# CY8C5868AXI_LP035 register map
File version: 0.1
CY8C58LP
Registers are 8-bit, read-write, no defined reset value unless marked. A register's access mark holds for its fields unless they carry their own. Offsets are from the block's base; lines under a group give offsets from that group; [hi:lo] are bit positions; {n}, {i} and the like mark numbered series; 'fields as' and 'values as' point back to an identical list; <NAME> marks a mode.

## Memory map
0x00000000 USBMIDI_1 — USBFS
0x00000000 MIDI1_UART — UART
0x00000000 Noise_Clk_Div
0x00000000 Tri_Divider
0x00000000 Length_Counter
0x00000000 Length_Counter_1
0x00000000 Counter_1
0x00000000 VDAC8_Noise
0x40006406 LFSR
0x40006471 volume_generator — Count7 debug registers
0x40006477 Control_Reg_2
0x4000647D Control_Reg_1
0x40006564 Status_Reg_1
0x40006574 Control_Reg_4
0x40006575 Count7_2 — Count7 debug registers
0x40006576 Noise_Vol_Clk_Div — Count7 debug registers
0x40006577 Count7_1 — Count7 debug registers
0x40006578 Control_Reg_3

## MIDI1_UART — UART
Base 0x00000000
0x4000642B RX_MIDI1_UART_RX_ADDRESS1 — RX Address1 Register
0x4000643B RX_MIDI1_UART_RX_ADDRESS2 — RX Address2 Register
0x4000644B RX_MIDI1_UART_RX_DATA — RX Data Register
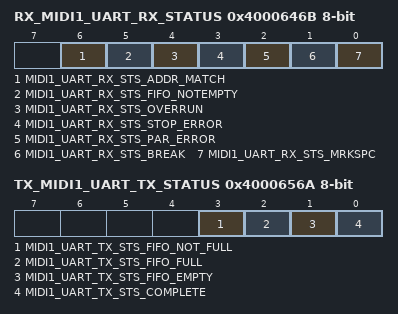
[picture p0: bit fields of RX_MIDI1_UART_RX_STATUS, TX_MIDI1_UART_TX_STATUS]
0x4000646B RX_MIDI1_UART_RX_STATUS — RX status register
  [6] MIDI1_UART_RX_STS_ADDR_MATCH ro, [5] MIDI1_UART_RX_STS_FIFO_NOTEMPTY ro, [4] MIDI1_UART_RX_STS_OVERRUN ro, [3] MIDI1_UART_RX_STS_STOP_ERROR ro, [2] MIDI1_UART_RX_STS_PAR_ERROR ro, [1] MIDI1_UART_RX_STS_BREAK ro, [0] MIDI1_UART_RX_STS_MRKSPC ro
0x4000654A TX_MIDI1_UART_TX_DATA — TX Data Register
0x4000656A TX_MIDI1_UART_TX_STATUS — TX status register
  [3] MIDI1_UART_TX_STS_FIFO_NOT_FULL ro, [2] MIDI1_UART_TX_STS_FIFO_FULL ro, [1] MIDI1_UART_TX_STS_FIFO_EMPTY ro, [0] MIDI1_UART_TX_STS_COMPLETE ro

## Count7_2 — Count7 debug registers
Base 0x40006575
Same registers: volume_generator 0x40006471, Noise_Vol_Clk_Div 0x40006576, Count7_1 0x40006577
0x00 COUNT 7-bit — Count value register
0x10 PERIOD 7-bit — Count7 period register

## Status_Reg_1
Base 0x40006564
0x00 Status_Reg_1_STATUS_REG
0x20 Status_Reg_1_MASK_REG
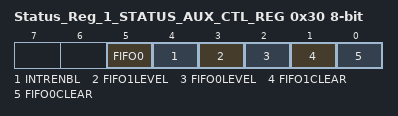
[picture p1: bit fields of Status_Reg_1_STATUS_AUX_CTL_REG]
0x30 Status_Reg_1_STATUS_AUX_CTL_REG
  [5] FIFO0 — FIFO0 clear
    1=ENABLED (Enable counter); 0=DISABLED (Disable counter)
  [4] INTRENBL — Enables or disables the Interrupt
    1=ENABLED (Interrupt enabled); 0=DISABLED (Interrupt disabled)
  [3] FIFO1LEVEL — FIFO level
    1=ENABLED (FIFO LVL: input mode: FIFO at least 1/2 empty; output mode: FIFO at least 1/2 full); 0=DISABLED (FIFO LVL: input mode: FIFO not full; output mode: FIFO not empty)
  [2] FIFO0LEVEL — FIFO level
    values as FIFO1LEVEL
  [1] FIFO1CLEAR — FIFO clear
    1=ENABLED (Clear FIFO state); 0=DISABLED (Normal FIFO operation)
  [0] FIFO0CLEAR — FIFO clear
    values as FIFO1CLEAR

## Control_Reg_3
Base 0x40006578
0x00 Control_Reg_3_CONTROL_REG

## Control_Reg_2
Base 0x40006477
Registers as Control_Reg_3 (with Control_Reg_3 read as Control_Reg_2).

## Control_Reg_4
Base 0x40006574
Registers as Control_Reg_3 (with Control_Reg_3 read as Control_Reg_4).

## Control_Reg_1
Base 0x4000647D
Registers as Control_Reg_3 (with Control_Reg_3 read as Control_Reg_1).

## Noise_Clk_Div
Base 0x00000000
0x400043A3 Noise_Clk_Div_GLOBAL_ENABLE — PM.ACT.CFG
  [3:0] en_timer — Enable timer/counters.
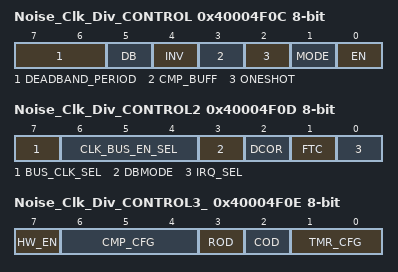
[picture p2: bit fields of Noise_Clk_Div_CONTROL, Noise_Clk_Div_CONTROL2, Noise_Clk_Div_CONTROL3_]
0x40004F0C Noise_Clk_Div_CONTROL — TMRx.CFG0
  [7:6] DEADBAND_PERIOD
  [5] DB — Deadband mode--Deadband phases phi1 and phi2 are outputted on CMP and TC output pins respectively.
    0=Timer (CMP and TC are output.); 1=Deadband (PHI1 (instead of CMP) and PHI2 (instead of TC) are output.)
  [4] INV — Invert sense of TIMEREN signal
  [3] CMP_BUFF — Buffer compare register. Compare register updates only on timer terminal count.
  [2] ONESHOT — Timer stops upon reaching stop condition defined by TMR_CFG bits. Can be restarted by asserting TIMER RESET or disabling and re-enabling block.
  [1] MODE — Mode. (0 = Timer; 1 = Comparator)
    0=Timer mode. CNT/CMP register holds timer count value.; 1=Comparator mode. CNT/CMP register holds comparator threshold value.
  [0] EN — Enables timer/comparator.
0x40004F0D Noise_Clk_Div_CONTROL2 — TMRx.CFG1
  [7] BUS_CLK_SEL — Bus Clock selection.
  [6:4] CLK_BUS_EN_SEL — Digital Global Clock selection.
  [3] DBMODE — Deadband mode (asynchronous/synchronous). CMP output pin is also affected when not in deadband mode (CFG0.DEADBAND).
  [2] DCOR — Disable Clear on Read (DCOR) of Status Register SR0.
  [1] FTC — First Terminal Count (FTC). Setting this bit forces a single pulse on the TC pin when first enabled.
    0=Disable_FTC (Disable the single cycle pulse, which signifies the timer is starting.); 1=Enable_FTC (Enable the single cycle pulse, which signifies the timer is starting.)
  [0] IRQ_SEL — Irq selection. (0 = raw interrupts; 1 = status register interrupts)
0x40004F0E Noise_Clk_Div_CONTROL3_ — TMRx.CFG2
  [7] HW_EN — When set Timer Enable controls counting.
  [6:4] CMP_CFG — Comparator configurations
    0=Equal (Compare Equal); 1=Less_than (Compare Less Than); 2=Less_than_or_equal (Compare Less Than or Equal .); 3=Greater (Compare Greater Than .); 4=Greater_than_or_equal (Compare Greater Than or Equal)
  [3] ROD — Reset On Disable (ROD). Resets internal state of output logic
  [2] COD — Clear On Disable (COD). Clears or gates outputs to zero.
  [1:0] TMR_CFG — Timer configuration (MODE = 0): 000 = Continuous; 001 = Pulsewidth; 010 = Period; 011 = Stop on IRQ
    0=Continuous (Timer runs while EN bit of CFG0 register is set to '1'.); 1=Pulsewidth (Timer runs from positive to negative edge of TIMEREN.); 2=Period (Timer runs from positive to positive edge of TIMEREN.); 3=Irq (Timer runs until IRQ.)
0x40004F10 Noise_Clk_Div_PERIOD 16-bit — TMRx.PER0 - Assigned Period
0x40004F12 Noise_Clk_Div_COUNTER 16-bit — TMRx.CNT_CMP0 - Current Down Counter Value
